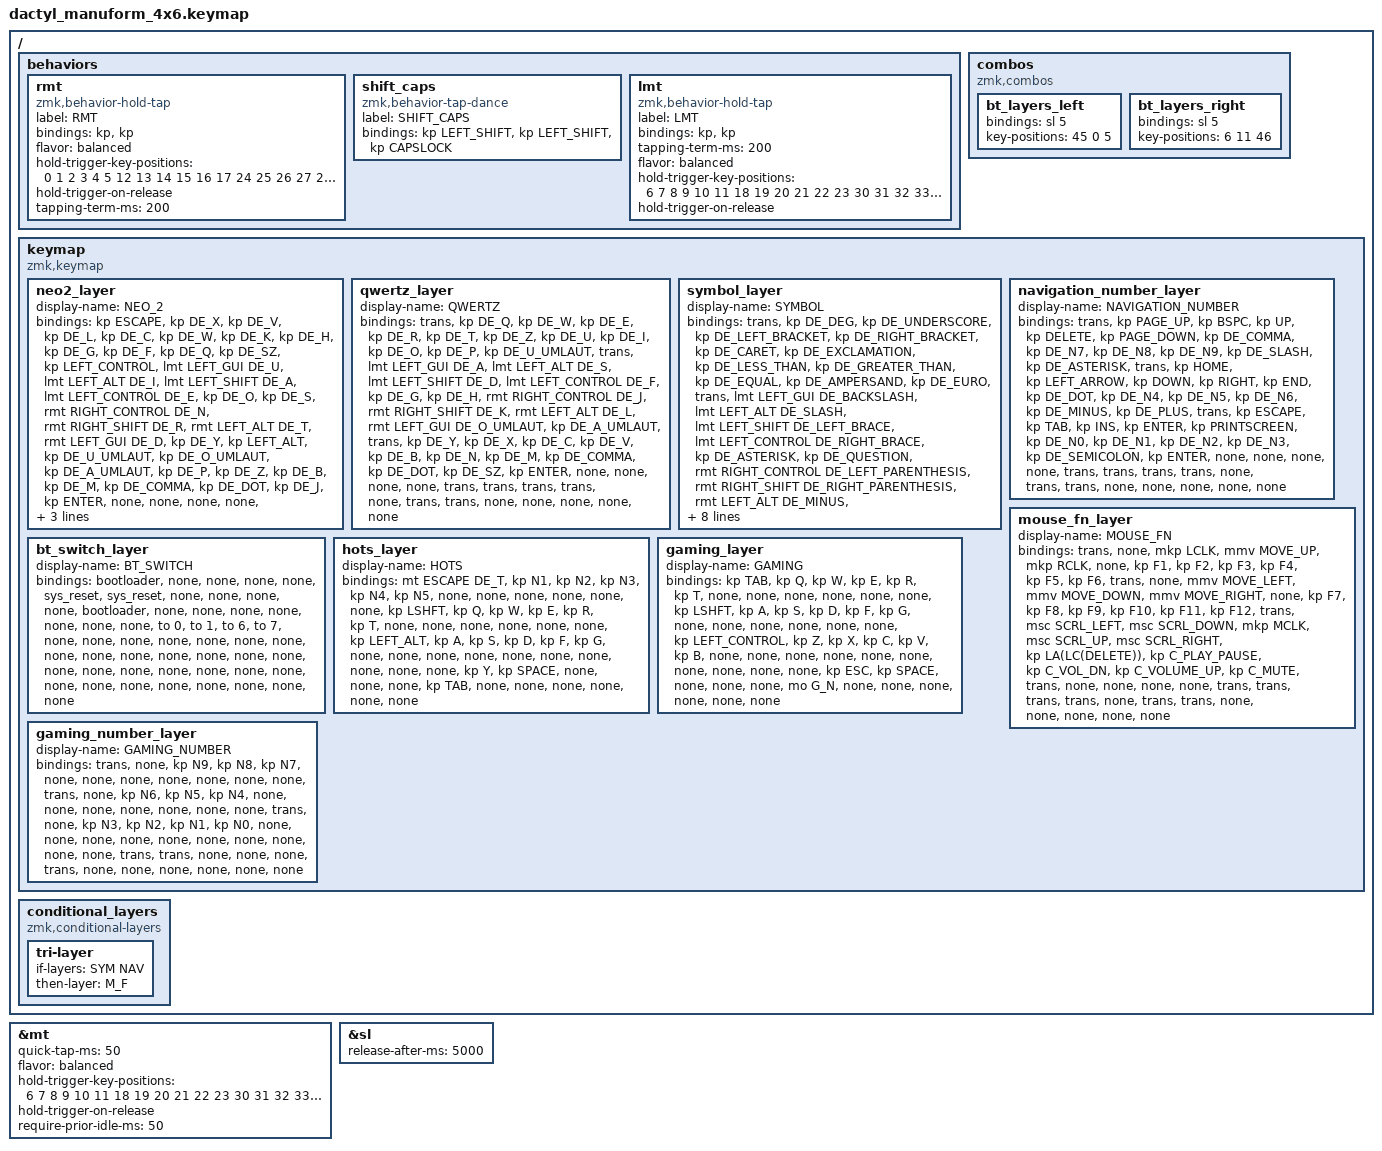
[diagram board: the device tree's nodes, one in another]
#include <behaviors.dtsi>
#include <dt-bindings/zmk/bt.h>
#include <dt-bindings/zmk/keys.h>
#include <dt-bindings/zmk/pointing.h>
#include "keys_de.h"

#define NEO 0
#define QWE 1
#define SYM 2
#define NAV 3
#define M_F 4
#define SYS 5
#define HTS 6
#define GAM 7
#define G_N 8

&mt {
    quick-tap-ms = <50>;
    flavor = "balanced";
    hold-trigger-key-positions = <6 7 8 9 10 11 18 19 20 21 22 23 30 31 32 33 34 35 42 43 46>;
    hold-trigger-on-release;
    require-prior-idle-ms = <50>;
};

&sl { release-after-ms = <5000>; };

/ {
    behaviors {
        rmt: rmt {
            compatible = "zmk,behavior-hold-tap";
            label = "RMT";
            bindings = <&kp>, <&kp>;
            #binding-cells = <2>;
            flavor = "balanced";
            hold-trigger-key-positions = <0 1 2 3 4 5 12 13 14 15 16 17 24 25 26 27 28 29 40 41 45>;
            hold-trigger-on-release;
            tapping-term-ms = <200>;
        };

        shift_caps: shift_caps {
            compatible = "zmk,behavior-tap-dance";
            label = "SHIFT_CAPS";
            #binding-cells = <0>;
            bindings = <&kp LEFT_SHIFT>, <&kp LEFT_SHIFT>, <&kp CAPSLOCK>;
        };

        lmt: lmt {
            compatible = "zmk,behavior-hold-tap";
            label = "LMT";
            bindings = <&kp>, <&kp>;
            #binding-cells = <2>;
            tapping-term-ms = <200>;
            flavor = "balanced";
            hold-trigger-key-positions = <6 7 8 9 10 11 18 19 20 21 22 23 30 31 32 33 34 35 42 43 46>;
            hold-trigger-on-release;
        };
    };

    combos {
        compatible = "zmk,combos";

        bt_layers_left {
            bindings = <&sl 5>;
            key-positions = <45 0 5>;
        };

        bt_layers_right {
            bindings = <&sl 5>;
            key-positions = <6 11 46>;
        };
    };

    /*
     * Binding order per layer (52 keys):
     *   0..11   top row    L then R
     *  12..23   mid row    L then R
     *  24..35   bot row    L then R
     *  36..37   corner L        ← &none
     *  38..39   corner R        ← &none
     *  40..41   inner thumb L   ← active (L-t1, L-t2)
     *  42..43   inner thumb R   ← active (R-t1, R-t2)
     *  44       outer top L-a   ← &none
     *  45       outer top L-b   ← active (L-t3)
     *  46       outer top R-a   ← active (R-t3)
     *  47       outer top R-b   ← &none
     *  48..49   outer bot L     ← &none
     *  50..51   outer bot R     ← &none
     */
    keymap {
        compatible = "zmk,keymap";

        neo2_layer {
            display-name = "NEO_2";
            bindings = <
&kp ESCAPE        &kp DE_X            &kp DE_V            &kp DE_L              &kp DE_C                &kp DE_W
&kp DE_K          &kp DE_H            &kp DE_G            &kp DE_F              &kp DE_Q                &kp DE_SZ
&kp LEFT_CONTROL  &lmt LEFT_GUI DE_U  &lmt LEFT_ALT DE_I  &lmt LEFT_SHIFT DE_A  &lmt LEFT_CONTROL DE_E  &kp DE_O
&kp DE_S          &rmt RIGHT_CONTROL DE_N &rmt RIGHT_SHIFT DE_R &rmt LEFT_ALT DE_T &rmt LEFT_GUI DE_D   &kp DE_Y
&kp LEFT_ALT      &kp DE_U_UMLAUT     &kp DE_O_UMLAUT     &kp DE_A_UMLAUT       &kp DE_P                &kp DE_Z
&kp DE_B          &kp DE_M            &kp DE_COMMA        &kp DE_DOT            &kp DE_J                &kp ENTER
&none  &none
&none  &none
&kp LEFT_GUI   &kp DE_SPACE
&mo SYM        &shift_caps
&none          &mo NAV
&mo NAV        &none
&none  &none
&none  &none
            >;
        };

        qwertz_layer {
            display-name = "QWERTZ";
            bindings = <
&trans  &kp DE_Q            &kp DE_W            &kp DE_E              &kp DE_R                &kp DE_T
&kp DE_Z  &kp DE_U          &kp DE_I            &kp DE_O              &kp DE_P                &kp DE_U_UMLAUT
&trans  &lmt LEFT_GUI DE_A  &lmt LEFT_ALT DE_S  &lmt LEFT_SHIFT DE_D  &lmt LEFT_CONTROL DE_F  &kp DE_G
&kp DE_H  &rmt RIGHT_CONTROL DE_J &rmt RIGHT_SHIFT DE_K &rmt LEFT_ALT DE_L &rmt LEFT_GUI DE_O_UMLAUT &kp DE_A_UMLAUT
&trans  &kp DE_Y            &kp DE_X            &kp DE_C              &kp DE_V                &kp DE_B
&kp DE_N  &kp DE_M          &kp DE_COMMA        &kp DE_DOT            &kp DE_SZ               &kp ENTER
&none  &none
&none  &none
&trans  &trans
&trans  &trans
&none   &trans
&trans  &none
&none  &none
&none  &none
            >;
        };

        symbol_layer {
            display-name = "SYMBOL";
            bindings = <
&trans  &kp DE_DEG                  &kp DE_UNDERSCORE       &kp DE_LEFT_BRACKET            &kp DE_RIGHT_BRACKET              &kp DE_CARET
&kp DE_EXCLAMATION  &kp DE_LESS_THAN &kp DE_GREATER_THAN   &kp DE_EQUAL                  &kp DE_AMPERSAND                  &kp DE_EURO
&trans  &lmt LEFT_GUI DE_BACKSLASH  &lmt LEFT_ALT DE_SLASH  &lmt LEFT_SHIFT DE_LEFT_BRACE  &lmt LEFT_CONTROL DE_RIGHT_BRACE  &kp DE_ASTERISK
&kp DE_QUESTION  &rmt RIGHT_CONTROL DE_LEFT_PARENTHESIS &rmt RIGHT_SHIFT DE_RIGHT_PARENTHESIS &rmt LEFT_ALT DE_MINUS &rmt LEFT_GUI DE_COLON &kp DE_AT
&trans  &kp DE_HASH                 &kp DE_DOLLAR           &kp DE_PIPE                    &kp DE_TILDE                      &kp DE_GRAVE
&kp DE_PLUS  &kp DE_PERCENT         &kp DE_DOUBLE_QUOTES    &kp DE_SINGLE_QUOTE            &kp DE_SEMICOLON                  &trans
&none  &none
&none  &none
&trans  &trans
&trans  &trans
&none   &trans
&trans  &none
&none  &none
&none  &none
            >;
        };

        navigation_number_layer {
            display-name = "NAVIGATION_NUMBER";
            bindings = <
&trans  &kp PAGE_UP  &kp BSPC        &kp UP    &kp DELETE  &kp PAGE_DOWN
&kp DE_COMMA  &kp DE_N7  &kp DE_N8  &kp DE_N9  &kp DE_SLASH  &kp DE_ASTERISK
&trans  &kp HOME     &kp LEFT_ARROW  &kp DOWN  &kp RIGHT   &kp END
&kp DE_DOT    &kp DE_N4  &kp DE_N5  &kp DE_N6  &kp DE_MINUS  &kp DE_PLUS
&trans  &kp ESCAPE   &kp TAB         &kp INS   &kp ENTER   &kp PRINTSCREEN
&kp DE_N0     &kp DE_N1  &kp DE_N2  &kp DE_N3  &kp DE_SEMICOLON  &kp ENTER
&none  &none
&none  &none
&trans  &trans
&trans  &trans
&none   &trans
&trans  &none
&none  &none
&none  &none
            >;
        };

        mouse_fn_layer {
            display-name = "MOUSE_FN";
            bindings = <
&trans  &none           &mkp LCLK       &mmv MOVE_UP    &mkp RCLK        &none
&kp F1  &kp F2          &kp F3          &kp F4          &kp F5           &kp F6
&trans  &none           &mmv MOVE_LEFT  &mmv MOVE_DOWN  &mmv MOVE_RIGHT  &none
&kp F7  &kp F8          &kp F9          &kp F10         &kp F11          &kp F12
&trans  &msc SCRL_LEFT  &msc SCRL_DOWN  &mkp MCLK       &msc SCRL_UP     &msc SCRL_RIGHT
&kp LA(LC(DELETE))  &kp C_PLAY_PAUSE  &kp C_VOL_DN  &kp C_VOLUME_UP  &kp C_MUTE  &trans
&none  &none
&none  &none
&trans  &trans
&trans  &trans
&none   &trans
&trans  &none
&none  &none
&none  &none
            >;
        };

        bt_switch_layer {
            display-name = "BT_SWITCH";
            bindings = <
&bootloader  &none  &none  &none  &none  &sys_reset
&sys_reset   &none  &none  &none  &none  &bootloader
&none        &none  &none  &none  &none  &none
&none        &to 0  &to 1  &to 6  &to 7  &none
&none        &none  &none  &none  &none  &none
&none        &none  &none  &none  &none  &none
&none  &none
&none  &none
&none  &none
&none  &none
&none  &none
&none  &none
&none  &none
&none  &none
            >;
        };

        hots_layer {
            display-name = "HOTS";
            bindings = <
&mt ESCAPE DE_T  &kp N1  &kp N2  &kp N3  &kp N4  &kp N5
&none  &none  &none  &none  &none  &none
&kp LSHFT        &kp Q   &kp W   &kp E   &kp R   &kp T
&none  &none  &none  &none  &none  &none
&kp LEFT_ALT     &kp A   &kp S   &kp D   &kp F   &kp G
&none  &none  &none  &none  &none  &none
&none  &none
&none  &none
&kp Y   &kp SPACE
&none   &none
&none   &kp TAB
&none   &none
&none  &none
&none  &none
            >;
        };

        gaming_layer {
            display-name = "GAMING";
            bindings = <
&kp TAB           &kp Q  &kp W  &kp E  &kp R  &kp T
&none  &none  &none  &none  &none  &none
&kp LSHFT         &kp A  &kp S  &kp D  &kp F  &kp G
&none  &none  &none  &none  &none  &none
&kp LEFT_CONTROL  &kp Z  &kp X  &kp C  &kp V  &kp B
&none  &none  &none  &none  &none  &none
&none  &none
&none  &none
&kp ESC    &kp SPACE
&none      &none
&none      &mo G_N
&none      &none
&none  &none
&none  &none
            >;
        };

        gaming_number_layer {
            display-name = "GAMING_NUMBER";
            bindings = <
&trans  &none  &kp N9  &kp N8  &kp N7  &none
&none  &none  &none  &none  &none  &none
&trans  &none  &kp N6  &kp N5  &kp N4  &none
&none  &none  &none  &none  &none  &none
&trans  &none  &kp N3  &kp N2  &kp N1  &kp N0
&none  &none  &none  &none  &none  &none
&none  &none
&none  &none
&trans  &trans
&none   &none
&none   &trans
&none   &none
&none  &none
&none  &none
            >;
        };
    };

    conditional_layers {
        compatible = "zmk,conditional-layers";

        tri-layer {
            if-layers = <SYM NAV>;
            then-layer = <M_F>;
        };
    };
};
